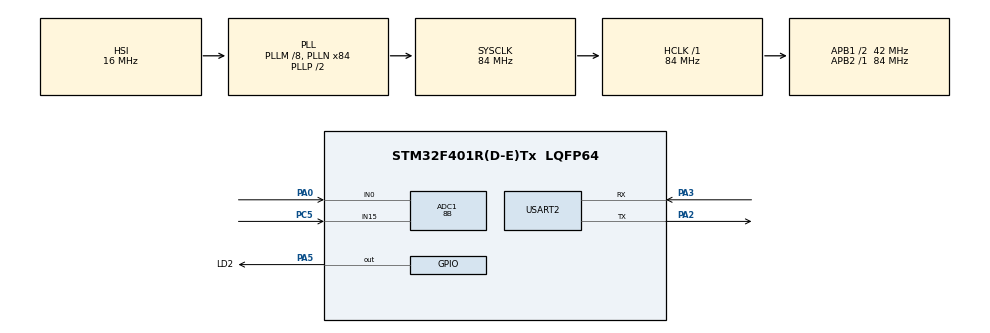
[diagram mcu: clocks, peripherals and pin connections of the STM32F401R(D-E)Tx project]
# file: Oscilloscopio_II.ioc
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ADC1.Channel-13\#ChannelRegularConversion=ADC_CHANNEL_15
ADC1.Channel-5\#ChannelRegularConversion=ADC_CHANNEL_0
ADC1.ContinuousConvMode=DISABLE
ADC1.DMAContinuousRequests=ENABLE
ADC1.EOCSelection=ADC_EOC_SEQ_CONV
ADC1.EnableAnalogWatchDog=true
ADC1.ExternalTrigConv=ADC_EXTERNALTRIGCONV_T3_TRGO
ADC1.HighThreshold=200
ADC1.ITMode=ENABLE
ADC1.InjNumberOfConversion=0
ADC1.LowThreshold=0
ADC1.NbrOfConversion=2
ADC1.NbrOfConversionFlag=1
ADC1.Rank-13\#ChannelRegularConversion=2
ADC1.Rank-5\#ChannelRegularConversion=1
ADC1.Resolution=ADC_RESOLUTION_8B
ADC1.SamplingTime-13\#ChannelRegularConversion=ADC_SAMPLETIME_3CYCLES
ADC1.SamplingTime-5\#ChannelRegularConversion=ADC_SAMPLETIME_3CYCLES
ADC1.ScanConvMode=ENABLE
ADC1.master=1
Dma.ADC1.0.Direction=DMA_PERIPH_TO_MEMORY
Dma.ADC1.0.FIFOMode=DMA_FIFOMODE_DISABLE
Dma.ADC1.0.Instance=DMA2_Stream0
Dma.ADC1.0.MemDataAlignment=DMA_MDATAALIGN_BYTE
Dma.ADC1.0.MemInc=DMA_MINC_ENABLE
Dma.ADC1.0.Mode=DMA_CIRCULAR
Dma.ADC1.0.PeriphDataAlignment=DMA_PDATAALIGN_BYTE
Dma.ADC1.0.PeriphInc=DMA_PINC_DISABLE
Dma.ADC1.0.Priority=DMA_PRIORITY_LOW
Dma.Request0=ADC1
Mcu.Family=STM32F4
Mcu.Name=STM32F401R(D-E)Tx
Mcu.Package=LQFP64
NVIC.ADC_IRQn=true\:1\:0\:true\:false\:true\:true\:true
NVIC.DMA2_Stream0_IRQn=true\:0\:0\:false\:false\:true\:false\:true
NVIC.PriorityGroup=NVIC_PRIORITYGROUP_4
NVIC.TIM3_IRQn=true\:0\:0\:false\:false\:true\:true\:true
NVIC.USART2_IRQn=true\:0\:0\:false\:false\:true\:true\:true
PA0-WKUP.Signal=ADCx_IN0
PA13.Mode=Serial_Wire
PA13.Signal=SYS_JTMS-SWDIO
PA14.Mode=Serial_Wire
PA14.Signal=SYS_JTCK-SWCLK
PA2.Mode=Asynchronous
PA2.Signal=USART2_TX
PA3.Mode=Asynchronous
PA3.Signal=USART2_RX
PA5.GPIO_Label=LD2
PA5.Signal=GPIO_Output
PC5.Signal=ADCx_IN15
ProjectManager.HeapSize=0x200
ProjectManager.StackSize=0x400
ProjectManager.TargetToolchain=STM32CubeIDE
RCC.48MHZClocksFreq_Value=42000000
RCC.AHBFreq_Value=84000000
RCC.APB1CLKDivider=RCC_HCLK_DIV2
RCC.APB1Freq_Value=42000000
RCC.APB1TimFreq_Value=84000000
RCC.APB2Freq_Value=84000000
RCC.APB2TimFreq_Value=84000000
RCC.CortexFreq_Value=84000000
RCC.HCLKFreq_Value=84000000
RCC.HSE_VALUE=25000000
RCC.HSI_VALUE=16000000
RCC.LSE_VALUE=32768
RCC.PLLM=8
RCC.PLLN=84
RCC.SYSCLKFreq_VALUE=84000000
RCC.SYSCLKSource=RCC_SYSCLKSOURCE_PLLCLK
RCC.VCOOutputFreq_Value=168000000
SH.ADCx_IN0.0=ADC1_IN0,IN0
SH.ADCx_IN15.0=ADC1_IN15,IN15
TIM3.AutoReloadPreload=TIM_AUTORELOAD_PRELOAD_ENABLE
TIM3.Channel-Output\ Compare1\ No\ Output=TIM_CHANNEL_1
TIM3.Period=11999
TIM3.Prescaler=699
TIM3.TIM_MasterOutputTrigger=TIM_TRGO_UPDATE
USART2.VirtualMode=VM_ASYNC
VP_TIM3_VS_ClockSourceINT.Mode=Internal
VP_TIM3_VS_no_output1.Mode=Output Compare1 No Output
board=custom

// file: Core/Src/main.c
/* USER CODE BEGIN Header */
/**
  ******************************************************************************
  * @file           : main.c
  * @brief          : Main program body
  ******************************************************************************
  * @attention
  *
  * <h2><center>&copy; Copyright (c) 2021 STMicroelectronics.
  * All rights reserved.</center></h2>
  *
  * This software component is licensed by ST under BSD 3-Clause license,
  * the "License"; You may not use this file except in compliance with the
  * License. You may obtain a copy of the License at:
  *                        opensource.org/licenses/BSD-3-Clause
  *
  ******************************************************************************
  */
/* USER CODE END Header */
#include "main.h"

/* USER CODE BEGIN Includes */
#include "opManage.h"
/* USER CODE END Includes */

ADC_HandleTypeDef hadc1;
DMA_HandleTypeDef hdma_adc1;

TIM_HandleTypeDef htim3;

UART_HandleTypeDef huart2;

void SystemClock_Config(void);
static void MX_GPIO_Init(void);
static void MX_DMA_Init(void);
static void MX_ADC1_Init(void);
static void MX_USART2_UART_Init(void);
static void MX_TIM3_Init(void);

int main(void)
{

  /* MCU Configuration--------------------------------------------------------*/

  /* Reset of all peripherals, Initializes the Flash interface and the Systick. */
  HAL_Init();

  /* Configure the system clock */
  SystemClock_Config();

  /* Initialize all configured peripherals */
  MX_GPIO_Init();
  MX_DMA_Init();
  MX_ADC1_Init();
  MX_USART2_UART_Init();
  MX_TIM3_Init();
  /* USER CODE BEGIN 2 */

  HWInit();	//Inizializza il DMA, il TIM3 e abilita gli interrupt in ricezione

  /* USER CODE END 2 */

  /* Infinite loop */
  while (1)
  {

    /* USER CODE BEGIN 3 */

	  opLoop();	//esegue il flusso di operazioni primario

  }
  /* USER CODE END 3 */
}

void SystemClock_Config(void)
{
  RCC_OscInitTypeDef RCC_OscInitStruct = {0};
  RCC_ClkInitTypeDef RCC_ClkInitStruct = {0};

  /** Configure the main internal regulator output voltage
  */
  __HAL_RCC_PWR_CLK_ENABLE();
  __HAL_PWR_VOLTAGESCALING_CONFIG(PWR_REGULATOR_VOLTAGE_SCALE2);
  /** Initializes the RCC Oscillators according to the specified parameters
  * in the RCC_OscInitTypeDef structure.
  */
  RCC_OscInitStruct.OscillatorType = RCC_OSCILLATORTYPE_HSI;
  RCC_OscInitStruct.HSIState = RCC_HSI_ON;
  RCC_OscInitStruct.HSICalibrationValue = RCC_HSICALIBRATION_DEFAULT;
  RCC_OscInitStruct.PLL.PLLState = RCC_PLL_ON;
  RCC_OscInitStruct.PLL.PLLSource = RCC_PLLSOURCE_HSI;
  RCC_OscInitStruct.PLL.PLLM = 8;
  RCC_OscInitStruct.PLL.PLLN = 84;
  RCC_OscInitStruct.PLL.PLLP = RCC_PLLP_DIV2;
  RCC_OscInitStruct.PLL.PLLQ = 4;
  if (HAL_RCC_OscConfig(&RCC_OscInitStruct) != HAL_OK)
  {
    Error_Handler();
  }
  /** Initializes the CPU, AHB and APB buses clocks
  */
  RCC_ClkInitStruct.ClockType = RCC_CLOCKTYPE_HCLK|RCC_CLOCKTYPE_SYSCLK
                              |RCC_CLOCKTYPE_PCLK1|RCC_CLOCKTYPE_PCLK2;
  RCC_ClkInitStruct.SYSCLKSource = RCC_SYSCLKSOURCE_PLLCLK;
  RCC_ClkInitStruct.AHBCLKDivider = RCC_SYSCLK_DIV1;
  RCC_ClkInitStruct.APB1CLKDivider = RCC_HCLK_DIV2;
  RCC_ClkInitStruct.APB2CLKDivider = RCC_HCLK_DIV1;

  if (HAL_RCC_ClockConfig(&RCC_ClkInitStruct, FLASH_LATENCY_2) != HAL_OK)
  {
    Error_Handler();
  }
}

static void MX_ADC1_Init(void)
{

  ADC_AnalogWDGConfTypeDef AnalogWDGConfig = {0};
  ADC_ChannelConfTypeDef sConfig = {0};

  /** Configure the global features of the ADC (Clock, Resolution, Data Alignment and number of conversion)
  */
  hadc1.Instance = ADC1;
  hadc1.Init.ClockPrescaler = ADC_CLOCK_SYNC_PCLK_DIV4;
  hadc1.Init.Resolution = ADC_RESOLUTION_8B;
  hadc1.Init.ScanConvMode = ENABLE;
  hadc1.Init.ContinuousConvMode = DISABLE;
  hadc1.Init.DiscontinuousConvMode = DISABLE;
  hadc1.Init.ExternalTrigConvEdge = ADC_EXTERNALTRIGCONVEDGE_RISING;
  hadc1.Init.ExternalTrigConv = ADC_EXTERNALTRIGCONV_T3_TRGO;
  hadc1.Init.DataAlign = ADC_DATAALIGN_RIGHT;
  hadc1.Init.NbrOfConversion = 2;
  hadc1.Init.DMAContinuousRequests = ENABLE;
  hadc1.Init.EOCSelection = ADC_EOC_SEQ_CONV;
  if (HAL_ADC_Init(&hadc1) != HAL_OK)
  {
    Error_Handler();
  }
  /** Configure the analog watchdog
  */
  AnalogWDGConfig.WatchdogMode = ADC_ANALOGWATCHDOG_SINGLE_REG;
  AnalogWDGConfig.HighThreshold = 199;
  AnalogWDGConfig.LowThreshold = 0;
  AnalogWDGConfig.Channel = ADC_CHANNEL_0;
  AnalogWDGConfig.ITMode = ENABLE;
  if (HAL_ADC_AnalogWDGConfig(&hadc1, &AnalogWDGConfig) != HAL_OK)
  {
    Error_Handler();
  }
  /** Configure for the selected ADC regular channel its corresponding rank in the sequencer and its sample time.
  */
  sConfig.Channel = ADC_CHANNEL_0;
  sConfig.Rank = 1;
  sConfig.SamplingTime = ADC_SAMPLETIME_3CYCLES;
  if (HAL_ADC_ConfigChannel(&hadc1, &sConfig) != HAL_OK)
  {
    Error_Handler();
  }
  /** Configure for the selected ADC regular channel its corresponding rank in the sequencer and its sample time.
  */
  sConfig.Channel = ADC_CHANNEL_15;
  sConfig.Rank = 2;
  if (HAL_ADC_ConfigChannel(&hadc1, &sConfig) != HAL_OK)
  {
    Error_Handler();
  }

}

static void MX_TIM3_Init(void)
{

  TIM_ClockConfigTypeDef sClockSourceConfig = {0};
  TIM_MasterConfigTypeDef sMasterConfig = {0};
  TIM_OC_InitTypeDef sConfigOC = {0};

  htim3.Instance = TIM3;
  htim3.Init.Prescaler = 700;
  htim3.Init.CounterMode = TIM_COUNTERMODE_UP;
  htim3.Init.Period = 1200;
  htim3.Init.ClockDivision = TIM_CLOCKDIVISION_DIV1;
  htim3.Init.AutoReloadPreload = TIM_AUTORELOAD_PRELOAD_ENABLE;
  if (HAL_TIM_Base_Init(&htim3) != HAL_OK)
  {
    Error_Handler();
  }
  sClockSourceConfig.ClockSource = TIM_CLOCKSOURCE_INTERNAL;
  if (HAL_TIM_ConfigClockSource(&htim3, &sClockSourceConfig) != HAL_OK)
  {
    Error_Handler();
  }
  if (HAL_TIM_OC_Init(&htim3) != HAL_OK)
  {
    Error_Handler();
  }
  sMasterConfig.MasterOutputTrigger = TIM_TRGO_UPDATE;
  sMasterConfig.MasterSlaveMode = TIM_MASTERSLAVEMODE_DISABLE;
  if (HAL_TIMEx_MasterConfigSynchronization(&htim3, &sMasterConfig) != HAL_OK)
  {
    Error_Handler();
  }
  sConfigOC.OCMode = TIM_OCMODE_TIMING;
  sConfigOC.Pulse = 0;
  sConfigOC.OCPolarity = TIM_OCPOLARITY_HIGH;
  sConfigOC.OCFastMode = TIM_OCFAST_DISABLE;
  if (HAL_TIM_OC_ConfigChannel(&htim3, &sConfigOC, TIM_CHANNEL_1) != HAL_OK)
  {
    Error_Handler();
  }

}

static void MX_USART2_UART_Init(void)
{

  huart2.Instance = USART2;
  huart2.Init.BaudRate = 115200;
  huart2.Init.WordLength = UART_WORDLENGTH_8B;
  huart2.Init.StopBits = UART_STOPBITS_1;
  huart2.Init.Parity = UART_PARITY_NONE;
  huart2.Init.Mode = UART_MODE_TX_RX;
  huart2.Init.HwFlowCtl = UART_HWCONTROL_NONE;
  huart2.Init.OverSampling = UART_OVERSAMPLING_16;
  if (HAL_UART_Init(&huart2) != HAL_OK)
  {
    Error_Handler();
  }

}

static void MX_DMA_Init(void)
{

  /* DMA controller clock enable */
  __HAL_RCC_DMA2_CLK_ENABLE();

  /* DMA interrupt init */
  /* DMA2_Stream0_IRQn interrupt configuration */
  HAL_NVIC_SetPriority(DMA2_Stream0_IRQn, 0, 0);
  HAL_NVIC_EnableIRQ(DMA2_Stream0_IRQn);

}

static void MX_GPIO_Init(void)
{
  GPIO_InitTypeDef GPIO_InitStruct = {0};

  /* GPIO Ports Clock Enable */
  __HAL_RCC_GPIOC_CLK_ENABLE();
  __HAL_RCC_GPIOH_CLK_ENABLE();
  __HAL_RCC_GPIOA_CLK_ENABLE();
  __HAL_RCC_GPIOB_CLK_ENABLE();
  __HAL_RCC_GPIOD_CLK_ENABLE();

  /*Configure GPIO pin Output Level */
  HAL_GPIO_WritePin(LD2_GPIO_Port, LD2_Pin, GPIO_PIN_RESET);

  /*Configure GPIO pins : PC13 PC14 PC15 PC0
                           PC1 PC2 PC3 PC4
                           PC6 PC7 PC8 PC9
                           PC10 PC11 PC12 */
  GPIO_InitStruct.Pin = GPIO_PIN_13|GPIO_PIN_14|GPIO_PIN_15|GPIO_PIN_0
                          |GPIO_PIN_1|GPIO_PIN_2|GPIO_PIN_3|GPIO_PIN_4
                          |GPIO_PIN_6|GPIO_PIN_7|GPIO_PIN_8|GPIO_PIN_9
                          |GPIO_PIN_10|GPIO_PIN_11|GPIO_PIN_12;
  GPIO_InitStruct.Mode = GPIO_MODE_ANALOG;
  GPIO_InitStruct.Pull = GPIO_NOPULL;
  HAL_GPIO_Init(GPIOC, &GPIO_InitStruct);

  /*Configure GPIO pins : PH0 PH1 */
  GPIO_InitStruct.Pin = GPIO_PIN_0|GPIO_PIN_1;
  GPIO_InitStruct.Mode = GPIO_MODE_ANALOG;
  GPIO_InitStruct.Pull = GPIO_NOPULL;
  HAL_GPIO_Init(GPIOH, &GPIO_InitStruct);

  /*Configure GPIO pins : PA1 PA4 PA6 PA7
                           PA8 PA9 PA10 PA11
                           PA12 PA15 */
  GPIO_InitStruct.Pin = GPIO_PIN_1|GPIO_PIN_4|GPIO_PIN_6|GPIO_PIN_7
                          |GPIO_PIN_8|GPIO_PIN_9|GPIO_PIN_10|GPIO_PIN_11
                          |GPIO_PIN_12|GPIO_PIN_15;
  GPIO_InitStruct.Mode = GPIO_MODE_ANALOG;
  GPIO_InitStruct.Pull = GPIO_NOPULL;
  HAL_GPIO_Init(GPIOA, &GPIO_InitStruct);

  /*Configure GPIO pin : LD2_Pin */
  GPIO_InitStruct.Pin = LD2_Pin;
  GPIO_InitStruct.Mode = GPIO_MODE_OUTPUT_PP;
  GPIO_InitStruct.Pull = GPIO_NOPULL;
  GPIO_InitStruct.Speed = GPIO_SPEED_FREQ_LOW;
  HAL_GPIO_Init(LD2_GPIO_Port, &GPIO_InitStruct);

  /*Configure GPIO pins : PB0 PB1 PB2 PB10
                           PB12 PB13 PB14 PB15
                           PB3 PB4 PB5 PB6
                           PB7 PB8 PB9 */
  GPIO_InitStruct.Pin = GPIO_PIN_0|GPIO_PIN_1|GPIO_PIN_2|GPIO_PIN_10
                          |GPIO_PIN_12|GPIO_PIN_13|GPIO_PIN_14|GPIO_PIN_15
                          |GPIO_PIN_3|GPIO_PIN_4|GPIO_PIN_5|GPIO_PIN_6
                          |GPIO_PIN_7|GPIO_PIN_8|GPIO_PIN_9;
  GPIO_InitStruct.Mode = GPIO_MODE_ANALOG;
  GPIO_InitStruct.Pull = GPIO_NOPULL;
  HAL_GPIO_Init(GPIOB, &GPIO_InitStruct);

  /*Configure GPIO pin : PD2 */
  GPIO_InitStruct.Pin = GPIO_PIN_2;
  GPIO_InitStruct.Mode = GPIO_MODE_ANALOG;
  GPIO_InitStruct.Pull = GPIO_NOPULL;
  HAL_GPIO_Init(GPIOD, &GPIO_InitStruct);

}

void Error_Handler(void)
{
  __disable_irq();
  while (1)
  {
  }
}

/************************ (C) COPYRIGHT STMicroelectronics *****END OF FILE****/
